# A31M22x register map
Vendor: ABOV Semiconductor Co., Ltd.; File version: 1.0
CPU: CM0PLUS r0p1, little endian, no MPU, no FPU, VTOR, 2 interrupt priority bits
Registers are 32-bit, read-write, reset 0x0 unless marked. A register's access mark holds for its fields unless they carry their own. Offsets are from the block's base; [hi:lo] are bit positions; {n}, {i} and the like mark numbered series.

## CFMC — CODE FLASH MEMORY CONTROLLER
Base 0x41000000
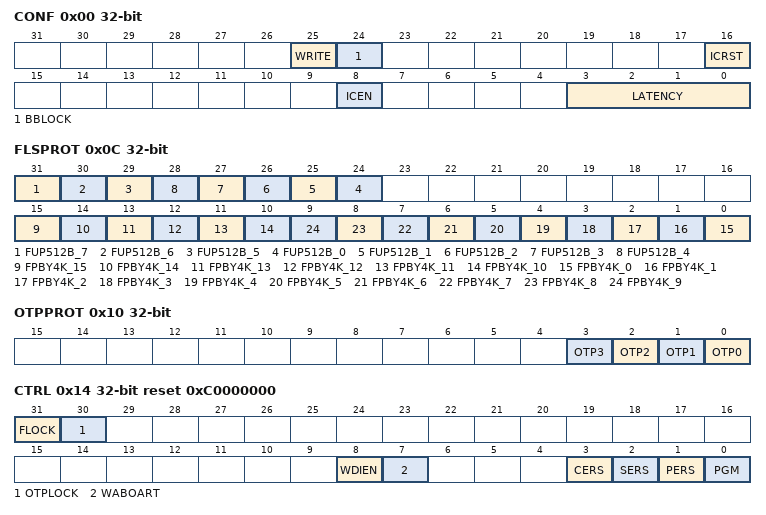
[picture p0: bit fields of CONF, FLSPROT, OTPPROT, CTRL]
0x00 CONF — Code Flash Control Register
  [25] WRITE — Code Flash Write Enable Bit
  [24] BBLOCK — Boot Block Lock Enable Bit
  [16] ICRST — Instruction Cache Reset Control Bit (Auto Clear)
  [8] ICEN — Instruction Cache Enable Bit
  [3:0] LATENCY — Flash Wait Value Bits
0x04 FLSKEY wo — Code Flash Access Key Register
  [31:0] FKEY — Flash Memory Access Key, KEY1(0x01234567) -> KEY2(0x12345678) -> KEY3(0x23456789)
0x08 OTPKEY wo — Code Flash OTP Access Key Register
  [31:0] OKEY — OTP Access Key Bits, KEY1(0x3456789A) -> KEY2(0x456789AB) -> KEY3(0x56789ABC)
0x0C FLSPROT — Code Flash Protection Register
  [31] FUP512B_7 — Flash upper 4KB Unprotection, 0x0000_FE00 0x0000_FFFF
  [30] FUP512B_6 — Flash upper 4KB Unprotection, 0x0000_FC00 0x0000_FDFF
  [29] FUP512B_5 — Flash upper 4KB Unprotection, 0x0000_FA00 0x0000_FBFF
  [n+24] FUP512B_{n} (n=0..4) — Flash upper 4KB Unprotection, 0x0000_F{200n:03} 0x0000_F{2n+1}FF
  [15] FPBY4K_15 — Flash 4KB Protection, 0x0000_F000 0x0000_FFFF
  [14] FPBY4K_14 — Flash 4KB Protection, 0x0000_E000 0x0000_EFFF
  [13] FPBY4K_13 — Flash 4KB Protection, 0x0000_D000 0x0000_DFFF
  [12] FPBY4K_12 — Flash 4KB Protection, 0x0000_C000 0x0000_CFFF
  [11] FPBY4K_11 — Flash 4KB Protection, 0x0000_B000 0x0000_BFFF
  [10] FPBY4K_10 — Flash 4KB Protection, 0x0000_A000 0x0000_AFFF
  [n] FPBY4K_{n} (n=0..9) — Flash 4KB Protection, 0x0000_{1000n:04} 0x0000_{n}FFF
0x10 OTPPROT — Code Flash OTP Protection Register
  [n] OTP{n} (n=0..3) — Option Area Protection {n} bit, 0x0F00_{200n:04} 0x0F00_{2n+1:02}FF
0x14 CTRL reset 0xC0000000 — Code Flash Access Control Register
  [31] FLOCK — Flash Lock Setting Bit
  [30] OTPLOCK — OTP Lock Setting Bit
  [8] WDIEN — Write done interrupt enable bit
  [7] WABOART — Write Abort enable bit
  [3] CERS — Chip Erase Mode Bit
  [2] SERS — Sector 2KB Erase Mode
  [1] PERS — Page Erase Mode
  [0] PGM — Program Mode
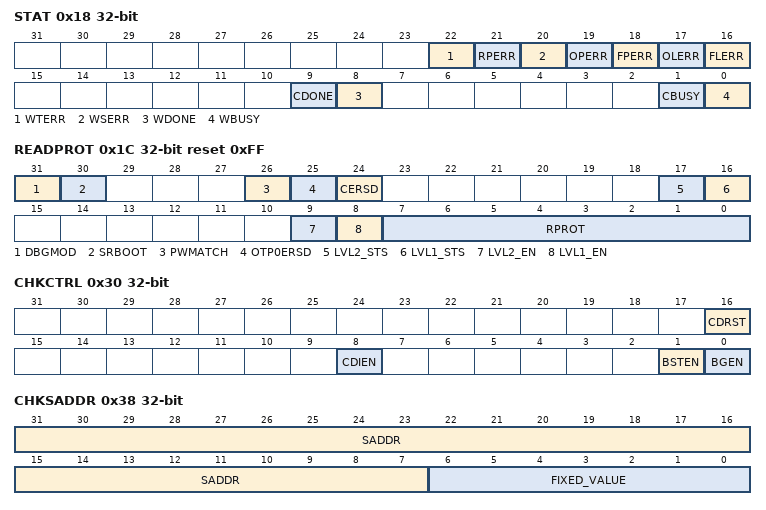
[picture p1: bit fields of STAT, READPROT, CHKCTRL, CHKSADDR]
0x18 STAT — Code Flash Access Status Register
  [22] WTERR — Write Timeout Error(Auto Cleared)
  [21] RPERR — Read Protect Error(Auto Cleared)
  [20] WSERR — Write Sequence Error (Auto Cleared)
  [19] OPERR — OTP Protect Error (Auto Cleared)
  [18] FPERR — Flash Protect Error (Auto Cleared)
  [17] OLERR — OTP Lock Error (Auto Cleared)
  [16] FLERR — Flash Lock Error (Auto Cleared)
  [9] CDONE — Checksum Done Check (Auto Cleared)
  [8] WDONE — Write Done Check (Auto Cleared)
  [1] CBUSY ro — Checksum Busy Check
    0=Not Busy (Checksum Not Busy); 1=Busy (Checksum Busy)
  [0] WBUSY ro — Write Busy Check
    0=Not Busy (Checksum Not Busy); 1=Busy (Checksum Busy)
0x1C READPROT reset 0xFF — Code Flash Read Protection Register
  [31] DBGMOD ro — Debug Operating Status Bit
  [30] SRBOOT ro — Sram Boot Mode Status Bit
  [26] PWMATCH ro — Password Match Flag Bit
  [25] OTP0ERSD ro — Chip Erase / OTP0 Erase Done Flag bit
  [24] CERSD ro — Chip Erase Done Flag Bit
  [17] LVL2_STS ro — Protection Level 2 Status Bit (Raw Data)
  [16] LVL1_STS ro — Protection Level 1 Status Bit (Raw Data)
  [9] LVL2_EN ro — Protection Level 2 Enable Bit
  [8] LVL1_EN ro — Protection Level 1 Enable Bit
  [7:0] RPROT — Read Protection Control Bit
0x20 PWIN wo — Code Flash Password Input Register
  [31:0] PWIN — Password Input Data Bit
0x30 CHKCTRL — Code Flash CRC Check Control Register
  [16] CDRST — CRC Data Reset (Auto Cleared)
    0=No Effect; 1=Reset
  [8] CDIEN — CRC Done Interrupt
    0=Disable; 1=Enable
  [1] BSTEN — Burst Mode
    0=Disable; 1=Enable
  [0] BGEN — Back Ground Mode
    0=Disable; 1=Enable
0x34 CHKDOUT reset 0xFFFF — Code Flash CRC Check Data Output Register
  [15:0] CDOUT ro — Flash CRC Data Output bit
0x38 CHKSADDR — Code Flash CRC Check Start Address Register
  [31:7] SADDR — Flash CRC Start Address bit
  [6:0] FIXED_VALUE ro — Fixed Vaule
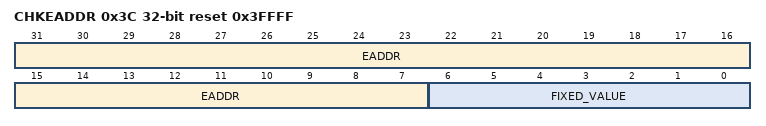
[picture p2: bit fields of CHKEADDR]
0x3C CHKEADDR reset 0x3FFFF — Code Flash CRC Check End Address Register
  [31:7] EADDR — Flash Checksum End Address bit
  [6:0] FIXED_VALUE ro
0x40 WTIMEOUT — Code Flash Write TimeOut Register
  [7:0] WTIMEOUT — Flash Write Timeout Setting Bit
0xF18 PWPRST wo — Code Flash Password Preset Register
  [31:0] PWPRST — Password Preset Data Bit
